VERSION "T7-sample"

NS_ :

BS_:

BU_: ECU Tester

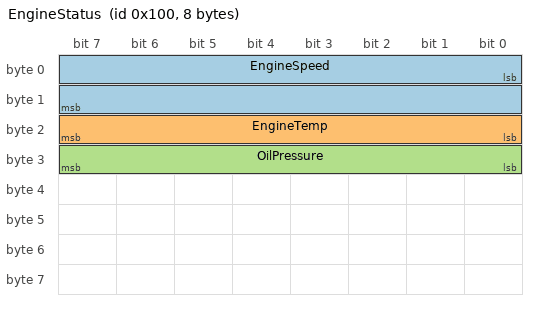
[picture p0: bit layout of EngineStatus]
BO_ 256 EngineStatus: 8 ECU
 SG_ EngineSpeed : 0|16@1+ (0.25,0) [0|16383.75] "rpm" Tester
 SG_ EngineTemp : 16|8@1+ (1,-40) [-40|215] "degC" Tester
 SG_ OilPressure : 24|8@1+ (2,0) [0|510] "kPa" Tester

BO_ 257 VehicleSpeed: 2 ECU
 SG_ Speed : 0|16@1+ (0.01,0) [0|655.35] "km/h" Tester

CM_ "VanillaBus T7 sample DBC (engine-side unpack only).";
CM_ BO_ 256 "Engine status for sample unpack goldens";
CM_ BO_ 257 "Vehicle speed";
